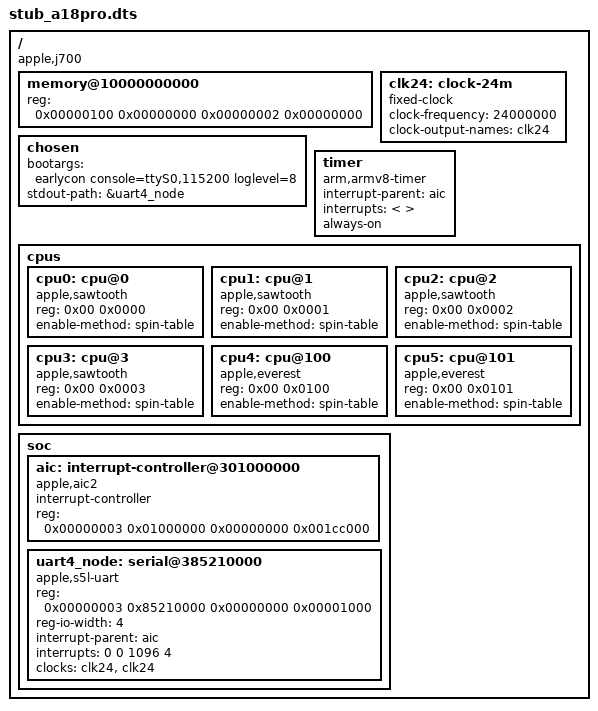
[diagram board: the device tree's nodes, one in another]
// SPDX-License-Identifier: GPL-2.0+ OR MIT
/*
 * Apple A18 Pro (t8140) — MacBook Neo stub device tree
 * Phase 1: serial console only
 *
 * GENERATED by asahi_neo/scripts/dump_adt.py — NOT for upstreaming.
 * Physical addresses from live ioreg dump, macOS 26.3.2 (25D2140).
 *
 * Verified physical addresses:
 *   AIC:   0x000301000000 (size 0x001cc000)
 *   uart4: 0x000385210000 (size 0x00004000) — wlan-debug UART
 *
 * Verified driver details (from Asahi Linux asahi branch):
 *   UART compat: "apple,s5l-uart" (driver: drivers/tty/serial/samsung_tty.c)
 *   earlycon: "earlycon=s3c2410,mmio32,0x385210000"
 *   Clock: 24 MHz fixed oscillator, names "uart" + "clk_uart_baud0"
 *   AIC #interrupt-cells: 4 — format: <type num flags irq_type>
 *   uart4 IRQ from ADT: 0x448 (1096 decimal)
 *
 * Confirmed via m1n1 first boot (2026-03-14):
 *   - DRAM base: 0x10000000000 ✓
 *   - AIC v3 @ 0x301000000 ✓
 *   - DT compatible: "apple,j700" (not "apple,j700ap")
 *   - Running in EL2 ✓
 *
 * TODO:
 *   - Verify AIC v3 interrupt specifier format for uart4 IRQ 0x448
 *   - Add ARM generic timer interrupts
 *   - Add CPU power domains / enable-method (Apple uses custom WFE)
 *   - Investigate MCC (mcc,t8140 unsupported) and pmgr ps-regs
 */

/dts-v1/;

/ {
	#address-cells = <2>;
	#size-cells = <2>;
	compatible = "apple,j700", "apple,t8140";

	memory@10000000000 {
		device_type = "memory";
		/* from ADT dram-base */
		reg = <0x00000100 0x00000000
		       0x00000002 0x00000000>;
	};

	/*
	 * 24 MHz fixed oscillator — UART clock source.
	 * All Apple Silicon UARTs run from the 24 MHz refclk.
	 */
	clk24: clock-24m {
		compatible = "fixed-clock";
		#clock-cells = <0>;
		clock-frequency = <24000000>;
		clock-output-names = "clk24";
	};

	chosen {
		/* earlycon uses s3c2410 driver (matches apple,s5l-uart) */
		/* earlycon is DT-driven via OF_EARLYCON_DECLARE — no address in cmdline */
		bootargs = "earlycon console=ttyS0,115200 loglevel=8";
		stdout-path = &uart4_node;
	};

	/* ARM generic timer — A18 Pro uses standard cntp/cntv timer */
	timer {
		compatible = "arm,armv8-timer";
		interrupt-parent = <&aic>;
		/* TODO: fill interrupt specifiers for A18 Pro AIC v3 */
		interrupts = </* TBD */>;
		always-on;
	};

	cpus {
		#address-cells = <2>;
		#size-cells = <0>;
		/* A18 Pro (MacBook Neo): 4 E-cores (apple,sawtooth) + 2 P-cores (apple,everest) */

		cpu0: cpu@0 {
			/* E-cluster, apple,sawtooth */
			device_type = "processor";
			compatible = "apple,sawtooth", "arm,armv8";
			reg = <0x00 0x0000>;
			enable-method = "spin-table";  /* TODO: verify — Apple uses custom WFE */
			/* TODO: operating-points, freq tables */
		};
		cpu1: cpu@1 {
			/* E-cluster, apple,sawtooth */
			device_type = "processor";
			compatible = "apple,sawtooth", "arm,armv8";
			reg = <0x00 0x0001>;
			enable-method = "spin-table";  /* TODO: verify — Apple uses custom WFE */
			/* TODO: operating-points, freq tables */
		};
		cpu2: cpu@2 {
			/* E-cluster, apple,sawtooth */
			device_type = "processor";
			compatible = "apple,sawtooth", "arm,armv8";
			reg = <0x00 0x0002>;
			enable-method = "spin-table";  /* TODO: verify — Apple uses custom WFE */
			/* TODO: operating-points, freq tables */
		};
		cpu3: cpu@3 {
			/* E-cluster, apple,sawtooth */
			device_type = "processor";
			compatible = "apple,sawtooth", "arm,armv8";
			reg = <0x00 0x0003>;
			enable-method = "spin-table";  /* TODO: verify — Apple uses custom WFE */
			/* TODO: operating-points, freq tables */
		};
		cpu4: cpu@100 {
			/* P-cluster, apple,everest */
			device_type = "processor";
			compatible = "apple,everest", "arm,armv8";
			reg = <0x00 0x0100>;
			enable-method = "spin-table";  /* TODO: verify — Apple uses custom WFE */
			/* TODO: operating-points, freq tables */
		};
		cpu5: cpu@101 {
			/* P-cluster, apple,everest */
			device_type = "processor";
			compatible = "apple,everest", "arm,armv8";
			reg = <0x00 0x0101>;
			enable-method = "spin-table";  /* TODO: verify — Apple uses custom WFE */
			/* TODO: operating-points, freq tables */
		};
	};

	soc {
		#address-cells = <2>;
		#size-cells = <2>;
		ranges;

		/* Apple Interrupt Controller v3 */
		aic: interrupt-controller@301000000 {
			compatible = "apple,aic2";  /* AIC v3 — use aic2 driver, TODO: verify compat string */
			#interrupt-cells = <4>;
			interrupt-controller;
			reg = <0x00000003 0x01000000
			       0x00000000 0x001cc000>;
		};

		/* UART4 (wlan-debug) — Apple s5l UART (Samsung-derived) */
		uart4_node: serial@385210000 {
			compatible = "apple,s5l-uart";
			reg = <0x00000003 0x85210000
			       0x00000000 0x00001000>;  /* 4KB; ADT maps 0x4000 but driver needs 0x1000 */
			reg-io-width = <4>;
			interrupt-parent = <&aic>;
			/*
			 * uart4 IRQ from ADT: 0x448 = 1096 decimal
			 * AIC v3 specifier: <AIC_IRQ 0 1096 IRQ_TYPE_LEVEL_HIGH>
			 * TODO: verify — AIC_IRQ=0, die=0, irq=1096, flags=4
			 */
			interrupts = <0 0 1096 4>;
			clocks = <&clk24>, <&clk24>;
			clock-names = "uart", "clk_uart_baud0";
			status = "okay";
		};

		/* TODO: add gpio, i2c, spi, pcie, nvme nodes for Phase 2+ */
	};
};
